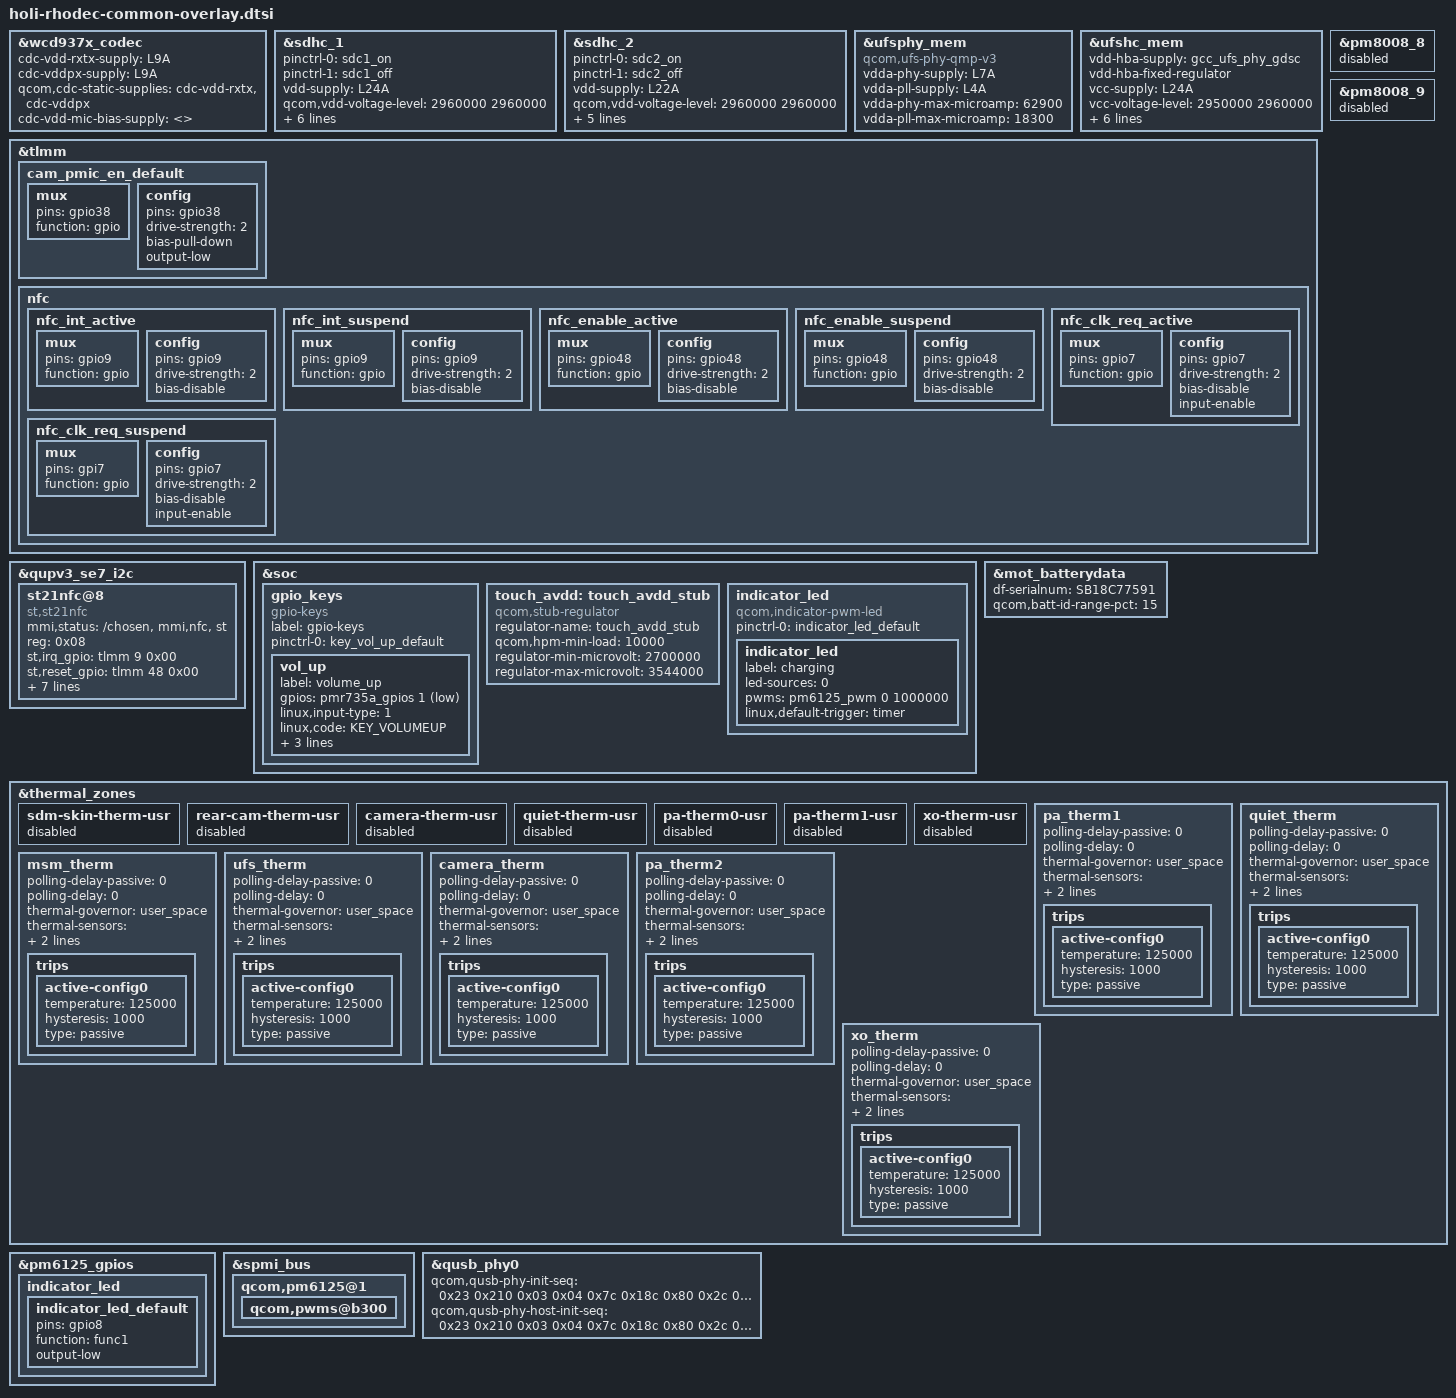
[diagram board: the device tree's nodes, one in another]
/* Copyright (c) 2021, The Linux Foundation. All rights reserved.
 *
 * This program is free software; you can redistribute it and/or modify
 * it under the terms of the GNU General Public License version 2 and
 * only version 2 as published by the Free Software Foundation.
 *
 * This program is distributed in the hope that it will be useful,
 * but WITHOUT ANY WARRANTY; without even the implied warranty of
 * MERCHANTABILITY or FITNESS FOR A PARTICULAR PURPOSE.  See the
 * GNU General Public License for more details.
 */
#include "holi-nopmi-moto-common-overlay.dtsi"

#include "holi-audio-wcd9370-aw882xx-acf-overlay.dtsi"
#include <dt-bindings/gpio/gpio.h>
#include <dt-bindings/input/linux-event-codes.h>
#include "rhodec-fps-overlay.dtsi"
#include "holi-pmic-overlay-pm6125.dtsi"
#include "holi-thermal-overlay-pm6125.dtsi"
#include "display/holi-sde-display-mtp-pm6125.dtsi"
#include "rhodec-display.dtsi"
#include "rhodec-touchscreen.dtsi"
#include "rhodec-fmr-overlay.dtsi"
#include "discrete_charging_holi.dtsi"

&wcd937x_codec {
	cdc-vdd-rxtx-supply = <&L9A>;
	cdc-vddpx-supply = <&L9A>;
	qcom,cdc-static-supplies = "cdc-vdd-rxtx",
				   "cdc-vddpx";
	/*
	 * Overriding cdc-vdd-mic-bias-supply to dummy value
	 * to avoid compilation errors as BOB is not definied
	 * for pm6125
	 */
	cdc-vdd-mic-bias-supply = <>;
};

/* Dummy LDO reference */
&sdhc_1 {
	status = "ok";

	pinctrl-names = "default", "sleep";
	pinctrl-0 = <&sdc1_on>;
	pinctrl-1 = <&sdc1_off>;

	vdd-supply = <&L24A>;
	qcom,vdd-voltage-level = <2960000 2960000>;
	qcom,vdd-current-level = <0 570000>;

	vdd-io-supply = <&L11A>;
	qcom,vdd-io-always-on;
	qcom,vdd-io-lpm-sup;
	qcom,vdd-io-voltage-level = <1800000 1800000>;
	qcom,vdd-io-current-level = <0 325000>;
};

&sdhc_2 {
	status = "ok";

	pinctrl-names = "default", "sleep";
	pinctrl-0 = <&sdc2_on>;
	pinctrl-1 = <&sdc2_off>;

	vdd-supply = <&L22A>;
	qcom,vdd-voltage-level = <2960000 2960000>;
	qcom,vdd-current-level = <0 800000>;

	vdd-io-supply = <&L5A>;
	qcom,vdd-io-voltage-level = <1800000 2960000>;
	qcom,vdd-io-current-level = <0 22000>;

	cd-gpios = <&tlmm 94 GPIO_ACTIVE_HIGH>;
};

&ufsphy_mem {
		compatible = "qcom,ufs-phy-qmp-v3";

		vdda-phy-supply = <&L7A>;
		vdda-pll-supply = <&L4A>;
		vdda-phy-max-microamp = <62900>;
		vdda-pll-max-microamp = <18300>;

		status = "ok";
};

&ufshc_mem {
		vdd-hba-supply = <&gcc_ufs_phy_gdsc>;
		vdd-hba-fixed-regulator;

		vcc-supply = <&L24A>;
		vcc-voltage-level = <2950000 2960000>;
		vcc-max-microamp = <800000>;

		vccq2-supply = <&L11A>;
		vccq2-max-microamp = <800000>;
		vccq2-voltage-level = <1800000 1800000>;

		qcom,vddp-ref-clk-supply = <&L4A>;
		qcom,vddp-ref-clk-max-microamp = <100>;

		status = "ok";
};

&tlmm {
	cam_pmic_en_default: cam_pmic_en_default {
		mux {
			pins = "gpio38";
			function = "gpio";
		};
		config {
			pins = "gpio38";
			drive-strength = <2>;
			bias-pull-down;
			output-low;
		};
	};

	nfc {
		nfc_int_active: nfc_int_active {
			/* active state */
			mux {
				/* GPIO 9: NFC Read Interrupt */
				pins = "gpio9";
				function = "gpio";
			};

			config {
				pins = "gpio9";
				drive-strength = <2>; /* 2 MA */
				bias-disable;
			};
		};

		nfc_int_suspend: nfc_int_suspend {
			/* sleep state */
			mux {
				/* GPIO 9: NFC Read Interrupt */
				pins = "gpio9";
				function = "gpio";
			};

			config {
				pins = "gpio9";
				drive-strength = <2>; /* 2 MA */
				bias-disable;
			};
		};

		nfc_enable_active: nfc_enable_active {
			mux {
				/* 48: Enable, 8: Firmware*/
				pins = "gpio48";
				function = "gpio";
			};

			config {
				pins = "gpio48";
				drive-strength = <2>; /* 2 MA */
				bias-disable;
			};
		};

		nfc_enable_suspend: nfc_enable_suspend {
			mux {
				/* 48: Enable, 8: Firmware */
				pins = "gpio48";
				function = "gpio";
			};

			config {
				pins = "gpio48";
				drive-strength = <2>; /* 2 MA */
				bias-disable;
			};
		};


		nfc_clk_req_active: nfc_clk_req_active {
			/* active state */
			mux {
				/* GPIO 7: NFC CLK Req*/
				pins = "gpio7";
				function = "gpio";
			};

			config {
				pins = "gpio7";
				drive-strength = <2>; /* 2 MA */
				bias-disable;
				input-enable;
			};
		};

		nfc_clk_req_suspend: nfc_clk_req_suspend {
			/* sleep state */
			mux {
				/* GPIO 7: NFC CLK Req */
				pins = "gpi7";
				function = "gpio";
			};

			config {
				pins = "gpio7";
				drive-strength = <2>; /* 2 MA */
				bias-disable;
				input-enable;
			};
		};
	};
};

&qupv3_se7_i2c {
	status = "ok";
	#address-cells = <1>;
	#size-cells = <0>;
	st21nfc@8 {
		compatible = "st,st21nfc";
		mmi,status = "/chosen", "mmi,nfc", "st";
		status = "ok";
		reg = <0x08>;
		st,irq_gpio = <&tlmm 9 0x00>;
		st,reset_gpio = <&tlmm 48 0x00>;
		st,clkreq_gpio = <&tlmm 7 0x00>;
		interrupt-parent = <&tlmm>;
		interrupts = <9 0>;
		interrupt-names = "nfc_irq";
		pinctrl-names = "nfc_active", "nfc_suspend";
		pinctrl-0 = <&nfc_int_active &nfc_enable_active
				&nfc_clk_req_active>;
		pinctrl-1 = <&nfc_int_suspend &nfc_enable_suspend
				&nfc_clk_req_suspend>;
	};
};



&pm8008_8 {
	status = "disabled";
};

&pm8008_9 {
	status = "disabled";
};

&soc {
	gpio_keys {
		compatible = "gpio-keys";
		label = "gpio-keys";

		pinctrl-names = "default";
		pinctrl-0 = <&key_vol_up_default>;

		vol_up {
			label = "volume_up";
			gpios = <&pmr735a_gpios 1 GPIO_ACTIVE_LOW>;
			linux,input-type = <1>;
			linux,code = <KEY_VOLUMEUP>;
			gpio-key,wakeup;
			debounce-interval = <15>;
			linux,can-disable;
		};
	};
};

&soc {
	touch_avdd: touch_avdd_stub {
		/*
		 * Touch eLDO controlled by gpio#53 is always ON.
		 * Using dummy regulator.
		 */
		compatible = "qcom,stub-regulator";
		regulator-name = "touch_avdd_stub";
		qcom,hpm-min-load = <10000>;
		regulator-min-microvolt = <2700000>;
		regulator-max-microvolt = <3544000>;
	};
};

&mot_batterydata {
	df-serialnum = "SB18C77591";
	qcom,batt-id-range-pct = <15>;
	#include "qg-batterydata-jk50-atl-5000mah.dtsi"
	#include "qg-batterydata-jk50-scud-5000mah.dtsi"
};

&thermal_zones {
	sdm-skin-therm-usr {
		status = "disabled";
	};
	rear-cam-therm-usr {
		status = "disabled";
	};
	camera-therm-usr {
		status = "disabled";
	};
	quiet-therm-usr {
		status = "disabled";
	};
	pa-therm0-usr {
		status = "disabled";
	};
	pa-therm1-usr {
		status = "disabled";
	};
	xo-therm-usr {
		status = "disabled";
	};

	pa_therm1 {
		polling-delay-passive = <0>;
		polling-delay = <0>;
		thermal-governor = "user_space";
		thermal-sensors = <&pm6125_adc_tm ADC5_AMUX_THM1_100K_PU>;
		wake-capable-sensor;
		trips {
			active-config0 {
				temperature = <125000>;
				hysteresis = <1000>;
				type = "passive";
			};
		};
	};

	quiet_therm {
		polling-delay-passive = <0>;
		polling-delay = <0>;
		thermal-governor = "user_space";
		thermal-sensors = <&pm6125_adc_tm ADC5_AMUX_THM2_100K_PU>;
		wake-capable-sensor;
		trips {
			active-config0 {
				temperature = <125000>;
				hysteresis = <1000>;
				type = "passive";
			};
		};
	};

	msm_therm {
		polling-delay-passive = <0>;
		polling-delay = <0>;
		thermal-governor = "user_space";
		thermal-sensors = <&pm6125_adc_tm_iio ADC5_GPIO1_100K_PU>;
		wake-capable-sensor;
		trips {
			active-config0 {
				temperature = <125000>;
				hysteresis = <1000>;
				type = "passive";
			};
		};
	};

	ufs_therm {
		polling-delay-passive = <0>;
		polling-delay = <0>;
		thermal-governor = "user_space";
		thermal-sensors = <&pm6125_adc_tm_iio ADC5_GPIO2_100K_PU>;
		wake-capable-sensor;
		trips {
			active-config0 {
				temperature = <125000>;
				hysteresis = <1000>;
				type = "passive";
			};
		};
	};

	camera_therm {
		polling-delay-passive = <0>;
		polling-delay = <0>;
		thermal-governor = "user_space";
		thermal-sensors = <&pm6125_adc_tm ADC5_GPIO3_100K_PU>;
		wake-capable-sensor;
		trips {
			active-config0 {
				temperature = <125000>;
				hysteresis = <1000>;
				type = "passive";
			};
		};
	};

	pa_therm2 {
		polling-delay-passive = <0>;
		polling-delay = <0>;
		thermal-governor = "user_space";
		thermal-sensors = <&pm6125_adc_tm ADC5_GPIO4_100K_PU>;
		wake-capable-sensor;
		trips {
			active-config0 {
				temperature = <125000>;
				hysteresis = <1000>;
				type = "passive";
			};
		};
	};

	xo_therm {
		polling-delay-passive = <0>;
		polling-delay = <0>;
		thermal-governor = "user_space";
		thermal-sensors = <&pmk8350_adc_tm PMK8350_ADC7_AMUX_THM1_100K_PU>;
		wake-capable-sensor;
		trips {
			active-config0 {
				temperature = <125000>;
				hysteresis = <1000>;
				type = "passive";
			};
		};
	};
};


&pm6125_gpios {
	indicator_led {
		indicator_led_default: indicator_led_default {
			pins = "gpio8";
			function = "func1";
			output-low;
		};
	};
};

&soc {
	indicator_led {
		compatible = "qcom,indicator-pwm-led";
		pinctrl-names = "default";
		pinctrl-0 = <&indicator_led_default>;
		indicator_led {
			label = "charging";
			led-sources = <0>;
			pwms = <&pm6125_pwm  0 1000000>;
			linux,default-trigger = "timer";
		};
	};
};

&spmi_bus {
	qcom,pm6125@1 {
		#address-cells = <1>;
		qcom,pwms@b300 {
			status = "ok";
		};
	};
};

&qusb_phy0 {
	qcom,qusb-phy-init-seq =
		/* <value reg_offset> */
		<0x23 0x210 /* PWR_CTRL1 */
		 0x03 0x04  /* PLL_ANALOG_CONTROLS_TWO */
		 0x7c 0x18c /* PLL_CLOCK_INVERTERS */
		 0x80 0x2c  /* PLL_CMODE */
		 0x0a 0x184 /* PLL_LOCK_DELAY */
		 0x19 0xb4  /* PLL_DIGITAL_TIMERS_TWO */
		 0x40 0x194 /* PLL_BIAS_CONTROL_1 */
		 0x1f 0x198 /* PLL_BIAS_CONTROL_2 */
		 0x21 0x214 /* PWR_CTRL2 */
		 0x08 0x220 /* IMP_CTRL1 */
		 0x58 0x224 /* IMP_CTRL2 */
		 0x47 0x240 /* TUNE1 */
		 0x29 0x244 /* TUNE2 */
		 0xca 0x248 /* TUNE3 */
		 0x04 0x24c /* TUNE4 */
		 0x03 0x250 /* TUNE5 */
		 0x30 0x23c /* CHG_CTRL2 */
		 0x22 0x210>; /* PWR_CTRL1 */

	qcom,qusb-phy-host-init-seq =
		/* <value reg_offset> */
		<0x23 0x210 /* PWR_CTRL1 */
		0x03 0x04  /* PLL_ANALOG_CONTROLS_TWO */
		0x7c 0x18c /* PLL_CLOCK_INVERTERS */
		0x80 0x2c  /* PLL_CMODE */
		0x0a 0x184 /* PLL_LOCK_DELAY */
		0x19 0xb4  /* PLL_DIGITAL_TIMERS_TWO */
		0x40 0x194 /* PLL_BIAS_CONTROL_1 */
		0x1f 0x198 /* PLL_BIAS_CONTROL_2 */
		0x21 0x214 /* PWR_CTRL2 */
		0x08 0x220 /* IMP_CTRL1 */
		0x58 0x224 /* IMP_CTRL2 */
		0x47 0x240 /* TUNE1 */
		0x29 0x244 /* TUNE2 */
		0xca 0x248 /* TUNE3 */
		0x04 0x24c /* TUNE4 */
		0x03 0x250 /* TUNE5 */
		0x30 0x23c /* CHG_CTRL2 */
		0x22 0x210>; /* PWR_CTRL1 */
};
